# PIC32CM6408PL10032 register map
Vendor: Microchip Technology; Series: PIC32CMPL10; File version: 0
CPU: CM0+ r0p0, little endian, no MPU, no FPU, VTOR, 2 interrupt priority bits, 15 interrupts
Registers are 32-bit, read-write, reset 0x0 unless marked. A register's access mark holds for its fields unless they carry their own. Offsets are from the block's base; [hi:lo] are bit positions; {n}, {i} and the like mark numbered series; 'fields as' and 'values as' point back to an identical list.

## ADC0 — Analog-to-Digital Converter
Base 0x42001C00; register names take the prefix ADC_
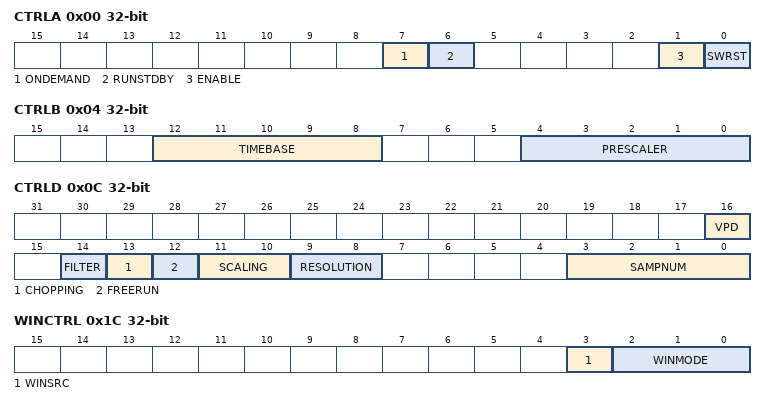
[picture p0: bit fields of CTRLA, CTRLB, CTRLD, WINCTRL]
0x00 CTRLA — Control A
  [7] ONDEMAND
  [6] RUNSTDBY — Run in Standby
  [1] ENABLE — ADC Enable
  [0] SWRST — Software Reset
0x04 CTRLB — Control B
  [12:8] TIMEBASE
  [4:0] PRESCALER
    {v}=DIV{v+2} (APB clock divided by {v+2}) (v=0..30)
0x08 CTRLC — Control C
  [2:0] REFSEL — Reference Selection
    0=VDD; 2=EXTVREF (External pin used as reference); 4=1V024 (Internal reference 1.024V); 5=2V048 (Internal reference 2.048V); 6=4V096 (Internal reference 4.096V); 7=2V500 (Internal reference 2.500V)
0x0C CTRLD — Control D
  [16] VPD — Voltage Pump Disable
  [14] FILTER — Low-Pass Filter
  [13] CHOPPING — Sign Chopping
  [12] FREERUN — Free-Running
  [11:10] SCALING — Result Scaling
    0=NORMAL (The ADC output of the sample or accumulated result is right adjusted); 1=LEFTADJ (The ADC output is left adjusted); 2=AVERAGE (The accumulated ADC result is averaged and right adjusted)
  [9:8] RESOLUTION — ADC Resolution
    0=12BIT (12-bit ADC Result); 1=13BIT (13-bit ADC Result); 2=10BIT (10-bit ADC Result); 3=8BIT (8-bit ADC Result)
  [3:0] SAMPNUM — Sample Accumulation Number Select
    0=NONE (No accumulation, single sample per conversion result); 1=ACC2 (2 samples accumulated); 2=ACC4 (4 samples accumulated); 3=ACC8 (8 samples accumulated); 4=ACC16 (16 samples accumulated); 5=ACC32 (32 samples accumulated); 6=ACC64 (64 samples accumulated); 7=ACC128 (128 samples accumulated); 8=ACC256 (256 samples accumulated); 9=ACC512 (512 samples accumulated); 10=ACC1024 (1024 samples accumulated)
0x10 CTRLE — Control E
  [7:0] SAMPLEN — Sample Length
0x1C WINCTRL — Window Control
  [3] WINSRC — Window Mode Source
    0=RESULT (Use RESULT[15:0] as Window Comparator source); 1=SAMPLE (Use SAMPLE[15:0] as Window Comparator source)
  [2:0] WINMODE — Window Comparator Mode
    0=NONE (No Window Comparison); 1=BELOW (OUTPUT 'less than' WINLT); 2=ABOVE (OUTPUT 'greater than' WINHT); 3=INSIDE (WINLT 'less than' OUTPUT 'less than' WINHT); 4=OUTSIDE (OUTPUT 'less than' WINLT or OUTPUT 'greater than'WINHT)
0x20 WINLT — Window Low Threshold
  [15:0] WINLT
0x24 WINHT — Window High Threshold
  [15:0] WINHT
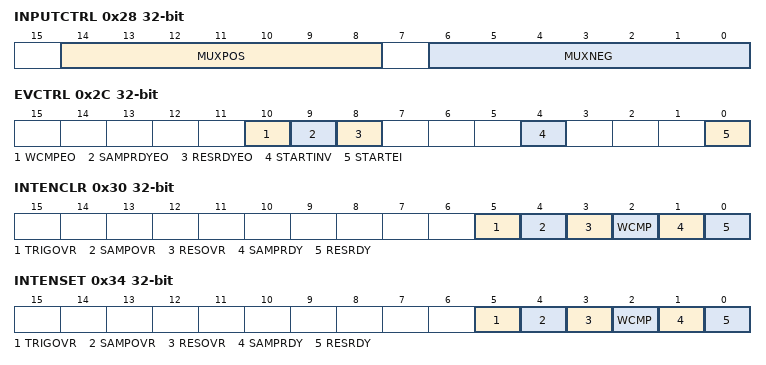
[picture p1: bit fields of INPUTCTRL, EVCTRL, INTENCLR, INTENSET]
0x28 INPUTCTRL — Input Multiplexer Control
  [14:8] MUXPOS — Positive Input Multiplexer
    {v}=AIN{v} (ADC AIN{v} Pin) (v=2..7); {v}=AIN{v} (ADC AIN{v} Pin) (v=16..29); 31=AIN31 (ADC AIN31 Pin); {v}=AIN{v} (ADC AIN{v} Pin) (v=40..47); 96=GND (Analog Ground); 97=VDDCOREDIV4 (1/4 Scaled Core Supply); 98=TEMPSENSE (Temperature Sensor); 100=VDDIODIV10 (1/10 Scaled VDDIO Supply); 101=VDDIO2DIV10 (1/10 Scaled VDDIO2 Supply); 105=ACVREFSCALE0 (Output from AC VREFSCALE0); 106=ACVREFSCALE1 (Output from AC VREFSCALE1); 112=TESTBUF (Test Buffer); 126=PTC
  [6:0] MUXNEG — Negative Input Multiplexer
    {v}=AIN{v} (ADC AIN{v} Pin) (v=2..7); {v}=AIN{v} (ADC AIN{v} Pin) (v=16..29); 31=AIN31 (ADC AIN31 Pin); {v}=AIN{v} (ADC AIN{v} Pin) (v=40..47); 96=GND (Analog Ground); 97=VREFP (Positive Reference)
0x2C EVCTRL — Event Control
  [10] WCMPEO — Window Comparator Event Output Enable
  [9] SAMPRDYEO — Sample Ready Event Output Enable
  [8] RESRDYEO — Result Ready Event Output Enable
  [4] STARTINV — Conversion Start Event Input Invert
  [0] STARTEI — Conversion Start Event Input Enable
0x30 INTENCLR write-1-clears — Interrupt Enable Clear
  [5] TRIGOVR — Trigger Overrun Interrupt Enable
  [4] SAMPOVR — Sample Overwrite Interrupt Enable
  [3] RESOVR — Result Overwrite Interrupt Enable
  [2] WCMP — Window Comparator Interrupt Enable
  [1] SAMPRDY — Sample Ready Interrupt Enable
  [0] RESRDY — Result Ready Interrupt Enable
0x34 INTENSET write-1-sets — Interrupt Enable Set
  fields as INTENCLR
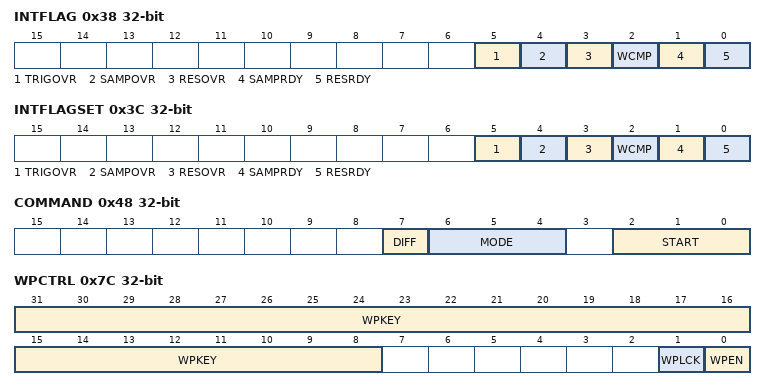
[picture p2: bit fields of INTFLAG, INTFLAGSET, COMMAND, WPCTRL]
0x38 INTFLAG write-1-clears — Interrupt Flag Status and Clear
  [5] TRIGOVR — Trigger Overrun Interrupt Flag
  [4] SAMPOVR — Sample Overwrite Interrupt Flag
  [3] RESOVR — Result Overwrite Interrupt Flag
  [2] WCMP — Window Comparator Interrupt Flag
  [1] SAMPRDY — Sample Ready Interrupt Flag
  [0] RESRDY — Result Ready Interrupt Flag
0x3C INTFLAGSET write-1-clears — Interrupt Flag Set
  fields as INTFLAG
0x40 STATUS ro
  [0] ADCBUSY
0x48 COMMAND
  [7] DIFF — Differential Mode
  [6:4] MODE
    0=NONE; 1=SINGLE (Single conversion); 2=SERIES (Series mode with accumulation, using a separate trigger for each conversion); 3=BURST (Burst mode with accumulation. A single trigger will initiate the number of conversions configured by CTRLD.SAMPNUM in one sequence.); 7=ACCTEST (Accumulator diagnostics mode)
  [2:0] START — Start Conversion
    0=STOP (Stop an ongoing conversion); 1=IMMEDIATE (Start a conversion immediately. This bit will be reset to STOP when the conversion is complete, unless Free-Running mode is enabled.); 2=INPUT (Start a conversion when a write to the INPUTCTRL register is performed); 4=EVENT (Start a conversion when an event is received by the ADC. This requires EVCTRL.STARTEI to be set to '1'.)
0x50 RESULT
  [31:0] RESULT — ADC Result
0x54 SAMPLE
  [15:0] SAMPLE — ADC Sample
0x6C DBGCTRL — Debug Control
  [0] DBGRUN — Debug Run
0x7C WPCTRL — Write Protection Control
  [31:8] WPKEY — Write Protection Key
    0x414443=KEY (Allow writes to the WPCTRL register)
  [1] WPLCK — Write Protection Lock
  [0] WPEN — Write Protection Enable

## Notices in the file
Copyright (c) 2026 Microchip Technology Inc.
SPDX-License-Identifier: Apache-2.0
Licensed under the Apache License, Version 2.0 (the "License");
you may not use this file except in compliance with the License.
You may obtain a copy of the License at
http://www.apache.org/licenses/LICENSE-2.0
Unless required by applicable law or agreed to in writing, software
distributed under the License is distributed on an "AS IS" BASIS,
WITHOUT WARRANTIES OR CONDITIONS OF ANY KIND, either express or implied.
See the License for the specific language governing permissions and
limitations under the License.
